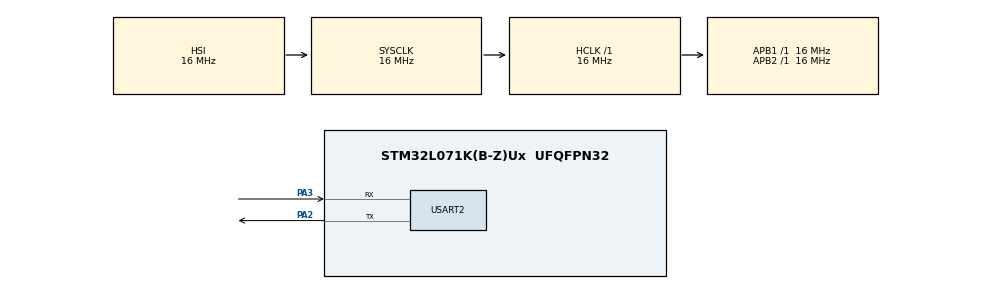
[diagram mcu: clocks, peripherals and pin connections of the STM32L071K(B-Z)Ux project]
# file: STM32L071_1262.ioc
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Mcu.Family=STM32L0
Mcu.Name=STM32L071K(B-Z)Ux
Mcu.Package=UFQFPN32
PA2.Mode=Asynchronous
PA2.Signal=USART2_TX
PA3.Mode=Asynchronous
PA3.Signal=USART2_RX
ProjectManager.HeapSize=0x200
ProjectManager.StackSize=0x400
ProjectManager.TargetToolchain=MDK-ARM V5
RCC.AHBFreq_Value=16000000
RCC.APB1Freq_Value=16000000
RCC.APB1TimFreq_Value=16000000
RCC.APB2Freq_Value=16000000
RCC.APB2TimFreq_Value=16000000
RCC.HCLKFreq_Value=16000000
RCC.HSI16_VALUE=16000000
RCC.HSI_VALUE=16000000
RCC.LSE_VALUE=32768
RCC.MSI_VALUE=2097000
RCC.SYSCLKFreq_VALUE=16000000
RCC.SYSCLKSource=RCC_SYSCLKSOURCE_HSI
RCC.VCOOutputFreq_Value=48000000
USART2.VirtualMode-Asynchronous=VM_ASYNC
board=custom

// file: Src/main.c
/* USER CODE BEGIN Header */
/**
  ******************************************************************************
  * @file           : main.c
  * @brief          : Main program body
  ******************************************************************************
  * @attention
  *
  * <h2><center>&copy; Copyright (c) 2020 STMicroelectronics.
  * All rights reserved.</center></h2>
  *
  * This software component is licensed by ST under BSD 3-Clause license,
  * the "License"; You may not use this file except in compliance with the
  * License. You may obtain a copy of the License at:
  *                        opensource.org/licenses/BSD-3-Clause
  *
  ******************************************************************************
  */
/* USER CODE END Header */

#include "main.h"
#include "usart.h"
#include "gpio.h"

/* USER CODE BEGIN Includes */
#include "stdio.h"

#include "utilities.h"
#include "board.h"
#include "gpio.h"
#include "LoRaMac.h"
#include "Commissioning.h"
/* USER CODE END Includes */

void SystemClock_Config(void);
/* USER CODE BEGIN PFP */
void MX_GPIO_Init(void);
/* USER CODE END PFP */

/* USER CODE BEGIN 0 */
#ifndef ACTIVE_REGION

#warning "No active region defined, LORAMAC_REGION_EU868 will be used as default."

#define ACTIVE_REGION LORAMAC_REGION_EU868

#endif

/*!
 * Defines the application data transmission duty cycle. 5s, value in [ms].
 */
#define APP_TX_DUTYCYCLE                            5000

/*!
 * Defines a random delay for application data transmission duty cycle. 1s,
 * value in [ms].
 */
#define APP_TX_DUTYCYCLE_RND                        1000

/*!
 * Default datarate
 */
#define LORAWAN_DEFAULT_DATARATE                    DR_0

/*!
 * LoRaWAN confirmed messages
 */
#define LORAWAN_CONFIRMED_MSG_ON                    false

/*!
 * LoRaWAN Adaptive Data Rate
 *
 * \remark Please note that when ADR is enabled the end-device should be static
 */
#define LORAWAN_ADR_ON                              1

#if defined( REGION_EU868 )

#include "LoRaMacTest.h"

/*!
 * LoRaWAN ETSI duty cycle control enable/disable
 *
 * \remark Please note that ETSI mandates duty cycled transmissions. Use only for test purposes
 */
#define LORAWAN_DUTYCYCLE_ON                        true

#endif

/*!
 * LoRaWAN application port
 */
#define LORAWAN_APP_PORT                            2

static uint8_t DevEui[] = LORAWAN_DEVICE_EUI;
static uint8_t AppEui[] = LORAWAN_APPLICATION_EUI;
static uint8_t AppKey[] = LORAWAN_APPLICATION_KEY;

#if( OVER_THE_AIR_ACTIVATION == 0 )

static uint8_t NwkSKey[] = LORAWAN_NWKSKEY;
static uint8_t AppSKey[] = LORAWAN_APPSKEY;

/*!
 * Device address
 */
static uint32_t DevAddr = LORAWAN_DEVICE_ADDRESS;

#endif

/*!
 * Application port
 */
static uint8_t AppPort = LORAWAN_APP_PORT;

/*!
 * User application data size
 */
static uint8_t AppDataSize = 16;
static uint8_t AppDataSizeBackup = 16;
/*!
 * User application data buffer size
 */
#define LORAWAN_APP_DATA_MAX_SIZE                           242

/*!
 * User application data
 */
static uint8_t AppData[LORAWAN_APP_DATA_MAX_SIZE];

/*!
 * Indicates if the node is sending confirmed or unconfirmed messages
 */
static uint8_t IsTxConfirmed = LORAWAN_CONFIRMED_MSG_ON;

/*!
 * Defines the application data transmission duty cycle
 */
static uint32_t TxDutyCycleTime;

/*!
 * Timer to handle the application data transmission duty cycle
 */
static TimerEvent_t TxNextPacketTimer;

/*!
 * Specifies the state of the application LED
 */
//static bool AppLedStateOn = false;

/*!
 * Timer to handle the state of LED1
 */
static TimerEvent_t Led1Timer;

/*!
 * Timer to handle the state of LED2
 */
static TimerEvent_t Led2Timer;

/*!
 * Indicates if a new packet can be sent
 */
static bool NextTx = true;

/*!
 * Device states
 */
static enum eDeviceState
{
    DEVICE_STATE_INIT,
    DEVICE_STATE_JOIN,
    DEVICE_STATE_SEND,
    DEVICE_STATE_CYCLE,
    DEVICE_STATE_SLEEP
}DeviceState;

/*!
 * LED GPIO pins objects
 */
extern Gpio_t Led1;
extern Gpio_t Led2;
//extern Gpio_t Led3;

/*!
 * \brief   MCPS-Confirm event function
 *
 * \param   [IN] mcpsConfirm - Pointer to the confirm structure,
 *               containing confirm attributes.
 */
static void McpsConfirm( McpsConfirm_t *mcpsConfirm )
{
    if( mcpsConfirm->Status == LORAMAC_EVENT_INFO_STATUS_OK )
    {
        switch( mcpsConfirm->McpsRequest )
        {
            case MCPS_UNCONFIRMED:
            {
                // Check Datarate
                // Check TxPower
                break;
            }
            case MCPS_CONFIRMED:
            {
                // Check Datarate
                // Check TxPower
                // Check AckReceived
                // Check NbTrials
                break;
            }
            case MCPS_PROPRIETARY:
            {
                break;
            }
            default:
                break;
        }

    }

}

/*!
 * \brief   MCPS-Indication event function
 *
 * \param   [IN] mcpsIndication - Pointer to the indication structure,
 *               containing indication attributes.
 */
static void McpsIndication( McpsIndication_t *mcpsIndication )
{
    if( mcpsIndication->Status != LORAMAC_EVENT_INFO_STATUS_OK )
    {
        return;
    }

    switch( mcpsIndication->McpsIndication )
    {
        case MCPS_UNCONFIRMED:
        {
            break;
        }
        case MCPS_CONFIRMED:
        {
            break;
        }
        case MCPS_PROPRIETARY:
        {
            break;
        }
        case MCPS_MULTICAST:
        {
            break;
        }
        default:
            break;
    }

}

/*!
 * \brief   MLME-Confirm event function
 *
 * \param   [IN] mlmeConfirm - Pointer to the confirm structure,
 *               containing confirm attributes.
 */
static void MlmeConfirm( MlmeConfirm_t *mlmeConfirm )
{
    switch( mlmeConfirm->MlmeRequest )
    {
        case MLME_JOIN:
        {
            if( mlmeConfirm->Status == LORAMAC_EVENT_INFO_STATUS_OK )
            {
                // Status is OK, node has joined the network
								printf("Status is OK, node has joined the network\r\n");
                //DeviceState = DEVICE_STATE_SEND;
            }
            else
            {
								printf("Join was not successful. Try to join again\r\n");
                // Join was not successful. Try to join again
//                MlmeReq_t mlmeReq;
//                mlmeReq.Type = MLME_JOIN;
//                mlmeReq.Req.Join.DevEui = DevEui;
//                mlmeReq.Req.Join.AppEui = AppEui;
//                mlmeReq.Req.Join.AppKey = AppKey;
//                mlmeReq.Req.Join.Datarate = LORAWAN_DEFAULT_DATARATE;

//                if( LoRaMacMlmeRequest( &mlmeReq ) == LORAMAC_STATUS_OK )
//                {
//                    DeviceState = DEVICE_STATE_SLEEP;
//                }
//                else
//                {
//                    DeviceState = DEVICE_STATE_CYCLE;
//                }
            }
            break;
        }
//        case MLME_LINK_CHECK:
//        {
//            if( mlmeConfirm->Status == LORAMAC_EVENT_INFO_STATUS_OK )
//            {
//                // Check DemodMargin
//                // Check NbGateways
//                if( ComplianceTest.Running == true )
//                {
//                    ComplianceTest.LinkCheck = true;
//                    ComplianceTest.DemodMargin = mlmeConfirm->DemodMargin;
//                    ComplianceTest.NbGateways = mlmeConfirm->NbGateways;
//                }
//            }
//            break;
//        }
        default:
            break;
    }
    //NextTx = true;
}

/*!
 * \brief   MLME-Indication event function
 *
 * \param   [IN] mlmeIndication - Pointer to the indication structure.
 */
static void MlmeIndication( MlmeIndication_t *mlmeIndication )
{

}

static TimerEvent_t Led2Timer;
void OnLed2TimerEvent( void )
{
    printf("OnLed2TimerEvent\r\n");
		TimerStart( &Led2Timer );
}

/* USER CODE END 0 */

int main(void)
{

  /* MCU Configuration--------------------------------------------------------*/

  /* Reset of all peripherals, Initializes the Flash interface and the Systick. */
  HAL_Init();

  /* Configure the system clock */
  SystemClock_Config();

  /* USER CODE BEGIN SysInit */
	LoRaMacStatus_t lora_state=0;
  /* USER CODE END SysInit */

  /* Initialize all configured peripherals */
  MX_GPIO_Init();
  MX_USART2_UART_Init();
  /* USER CODE BEGIN 2 */
	BoardInitMcu();
	LoRaMacPrimitives_t LoRaMacPrimitives;
	LoRaMacCallback_t LoRaMacCallbacks;
	MibRequestConfirm_t mibReq;

	LoRaMacPrimitives.MacMcpsConfirm = McpsConfirm;
	LoRaMacPrimitives.MacMcpsIndication = McpsIndication;
	LoRaMacPrimitives.MacMlmeConfirm = MlmeConfirm;
	LoRaMacPrimitives.MacMlmeIndication = MlmeIndication;
	LoRaMacCallbacks.GetBatteryLevel = BoardGetBatteryLevel;
	lora_state=LoRaMacInitialization( &LoRaMacPrimitives, &LoRaMacCallbacks, ACTIVE_REGION );
	printf("LoRaMacInitialization %d\r\n",lora_state);

	mibReq.Type = MIB_ADR;
	mibReq.Param.AdrEnable = LORAWAN_ADR_ON;
	LoRaMacMibSetRequestConfirm( &mibReq );

	mibReq.Type = MIB_PUBLIC_NETWORK;
	mibReq.Param.EnablePublicNetwork = LORAWAN_PUBLIC_NETWORK;
	LoRaMacMibSetRequestConfirm( &mibReq );

	mibReq.Type = MIB_DEVICE_CLASS;
	mibReq.Param.Class = CLASS_C;
	LoRaMacMibSetRequestConfirm( &mibReq );

	//DeviceState = DEVICE_STATE_JOIN;
	MlmeReq_t mlmeReq;
	mlmeReq.Type = MLME_JOIN;

	mlmeReq.Req.Join.DevEui = DevEui;
	mlmeReq.Req.Join.AppEui = AppEui;
	mlmeReq.Req.Join.AppKey = AppKey;
	mlmeReq.Req.Join.Datarate = LORAWAN_DEFAULT_DATARATE;

	if( LoRaMacMlmeRequest( &mlmeReq ) == LORAMAC_STATUS_OK )
	{
		/******printf******/
		DeviceState = DEVICE_STATE_SLEEP;
	}
	else
	{
		DeviceState = DEVICE_STATE_CYCLE;
	}
	TimerInit( &Led2Timer, OnLed2TimerEvent );
	TimerSetValue( &Led2Timer, 5000 );
	TimerStart( &Led2Timer );
  /* USER CODE END 2 */

  /* Infinite loop */
  while (1)
  {

    /* USER CODE BEGIN 3 */
		HAL_Delay(1000);
		//printf("SX1262\r\n");
  }
  /* USER CODE END 3 */
}

void SystemClock_Config(void)
{
  RCC_OscInitTypeDef RCC_OscInitStruct = {0};
  RCC_ClkInitTypeDef RCC_ClkInitStruct = {0};
  RCC_PeriphCLKInitTypeDef PeriphClkInit = {0};

  /** Configure the main internal regulator output voltage
  */
  __HAL_PWR_VOLTAGESCALING_CONFIG(PWR_REGULATOR_VOLTAGE_SCALE1);
  /** Initializes the CPU, AHB and APB busses clocks
  */
  RCC_OscInitStruct.OscillatorType = RCC_OSCILLATORTYPE_HSI|RCC_OSCILLATORTYPE_LSE;
  RCC_OscInitStruct.HSIState = RCC_HSI_ON;
	RCC_OscInitStruct.LSEState = RCC_LSE_ON;
  RCC_OscInitStruct.HSICalibrationValue = RCC_HSICALIBRATION_DEFAULT;
  RCC_OscInitStruct.PLL.PLLState = RCC_PLL_NONE;
  if (HAL_RCC_OscConfig(&RCC_OscInitStruct) != HAL_OK)
  {
    Error_Handler();
  }
  /** Initializes the CPU, AHB and APB busses clocks
  */
  RCC_ClkInitStruct.ClockType = RCC_CLOCKTYPE_HCLK|RCC_CLOCKTYPE_SYSCLK
                              |RCC_CLOCKTYPE_PCLK1|RCC_CLOCKTYPE_PCLK2;
  RCC_ClkInitStruct.SYSCLKSource = RCC_SYSCLKSOURCE_HSI;
  RCC_ClkInitStruct.AHBCLKDivider = RCC_SYSCLK_DIV1;
  RCC_ClkInitStruct.APB1CLKDivider = RCC_HCLK_DIV1;
  RCC_ClkInitStruct.APB2CLKDivider = RCC_HCLK_DIV1;

  if (HAL_RCC_ClockConfig(&RCC_ClkInitStruct, FLASH_LATENCY_0) != HAL_OK)
  {
    Error_Handler();
  }
  PeriphClkInit.PeriphClockSelection = RCC_PERIPHCLK_USART2;
  PeriphClkInit.Usart2ClockSelection = RCC_USART2CLKSOURCE_PCLK1;
  if (HAL_RCCEx_PeriphCLKConfig(&PeriphClkInit) != HAL_OK)
  {
    Error_Handler();
  }

	PeriphClkInit.PeriphClockSelection = RCC_PERIPHCLK_RTC;
	PeriphClkInit.RTCClockSelection = RCC_RTCCLKSOURCE_LSE;
	if( HAL_RCCEx_PeriphCLKConfig( &PeriphClkInit ) != HAL_OK )
	{
		assert_param( FAIL );
	}
}

/* USER CODE BEGIN 4 */
void MX_GPIO_Init(void)
{

  GPIO_InitTypeDef GPIO_InitStruct = {0};

  /* GPIO Ports Clock Enable */
  __HAL_RCC_GPIOC_CLK_ENABLE();
  __HAL_RCC_GPIOA_CLK_ENABLE();
  __HAL_RCC_GPIOB_CLK_ENABLE();

  /*Configure GPIO pins : PC14 PC15 */
  GPIO_InitStruct.Pin = GPIO_PIN_14|GPIO_PIN_15;
  GPIO_InitStruct.Mode = GPIO_MODE_ANALOG;
  GPIO_InitStruct.Pull = GPIO_NOPULL;
  HAL_GPIO_Init(GPIOC, &GPIO_InitStruct);

  /*Configure GPIO pins : PA0 PA1 PA4 PA5
                           PA6 PA7 PA8 PA9
                           PA10 PA11 PA12 PA13
                           PA14 */
  GPIO_InitStruct.Pin = GPIO_PIN_0|GPIO_PIN_1|GPIO_PIN_4|GPIO_PIN_5
                          |GPIO_PIN_6|GPIO_PIN_7|GPIO_PIN_8|GPIO_PIN_9
                          |GPIO_PIN_10|GPIO_PIN_11|GPIO_PIN_12|GPIO_PIN_13
                          |GPIO_PIN_14;
  GPIO_InitStruct.Mode = GPIO_MODE_ANALOG;
  GPIO_InitStruct.Pull = GPIO_NOPULL;
  HAL_GPIO_Init(GPIOA, &GPIO_InitStruct);

  /*Configure GPIO pins : PB0 PB1 PB4 PB5
                           PB6 PB7 */
  GPIO_InitStruct.Pin = GPIO_PIN_0|GPIO_PIN_1|GPIO_PIN_4|GPIO_PIN_5
                          |GPIO_PIN_6|GPIO_PIN_7;
  GPIO_InitStruct.Mode = GPIO_MODE_ANALOG;
  GPIO_InitStruct.Pull = GPIO_NOPULL;
  HAL_GPIO_Init(GPIOB, &GPIO_InitStruct);

}

/* USER CODE END 4 */

void Error_Handler(void)
{
}

/************************ (C) COPYRIGHT STMicroelectronics *****END OF FILE****/
